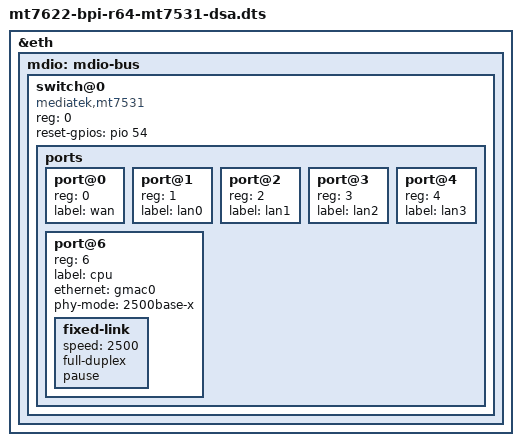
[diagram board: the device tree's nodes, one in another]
/*
 * Copyright (c) 2018 MediaTek Inc.
 * Author: Ryder Lee <ryder.lee@mediatek.com>
 *
 * SPDX-License-Identifier: (GPL-2.0 OR MIT)
 */

/dts-v1/;

#include "mt7622-bananapi-bpi-r64.dts"

/ {

};

&eth {
	mdio: mdio-bus {
		switch@0 {
			compatible = "mediatek,mt7531";
			reg = <0>;
			reset-gpios = <&pio 54 0>;

			ports {
				#address-cells = <1>;
				#size-cells = <0>;

				port@0 {
					reg = <0>;
					label = "wan";
				};

				port@1 {
					reg = <1>;
					label = "lan0";
				};

				port@2 {
					reg = <2>;
					label = "lan1";
				};

				port@3 {
					reg = <3>;
					label = "lan2";
				};

				port@4 {
					reg = <4>;
					label = "lan3";
				};

				port@6 {
					reg = <6>;
					label = "cpu";
					ethernet = <&gmac0>;
					phy-mode = "2500base-x";

					fixed-link {
						speed = <2500>;
						full-duplex;
						pause;
					};
				};
			};
		};

	};
};
